# mc200 register map
Registers are 32-bit, access not given, no defined reset value unless marked. A register's access mark holds for its fields unless they carry their own. Addresses are absolute; registers are grouped by the start of their names; [hi:lo] are bit positions; {n}, {i} and the like mark numbered series.

## UART2
0x48020000 UART2_RBR_THR_DLL
  [7:0] RBR_THR_DLL
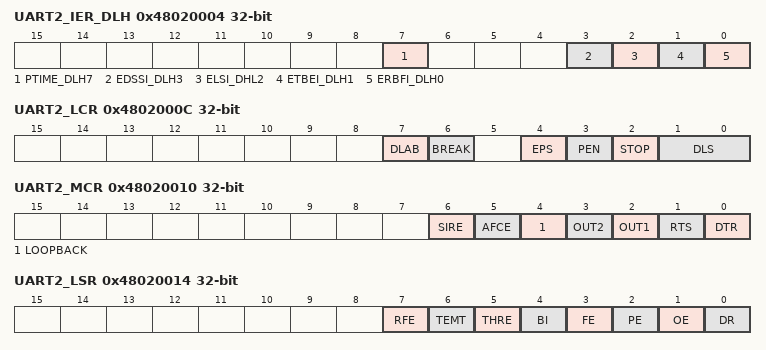
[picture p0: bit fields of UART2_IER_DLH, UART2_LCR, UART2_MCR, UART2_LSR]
0x48020004 UART2_IER_DLH
  [7] PTIME_DLH7, [3] EDSSI_DLH3, [2] ELSI_DHL2, [1] ETBEI_DLH1, [0] ERBFI_DLH0
0x48020008 UART2_IIR_FCR
  [31:0] DATA
0x4802000C UART2_LCR
  [7] DLAB, [6] BREAK, [4] EPS, [3] PEN, [2] STOP, [1:0] DLS
0x48020010 UART2_MCR
  [6] SIRE, [5] AFCE, [4] LOOPBACK, [3] OUT2, [2] OUT1, [1] RTS, [0] DTR
0x48020014 UART2_LSR
  [7] RFE, [6] TEMT, [5] THRE, [4] BI, [3] FE, [2] PE, [1] OE, [0] DR
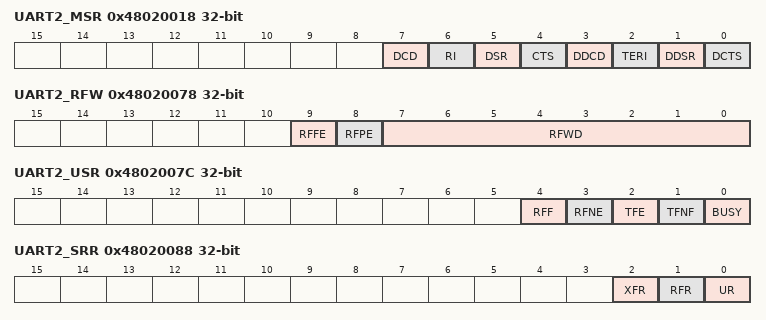
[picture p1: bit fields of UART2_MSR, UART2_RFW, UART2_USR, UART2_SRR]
0x48020018 UART2_MSR
  [7] DCD, [6] RI, [5] DSR, [4] CTS, [3] DDCD, [2] TERI, [1] DDSR, [0] DCTS
0x4802001C UART2_SCR
  [7:0] SCR
0x48020020 UART2_LPDLL
  [7:0] LPDLL
0x48020024 UART2_LPDLH
  [7:0] LPDLH
{0x48020030+4i} UART2_SRBR_STHR{i} (i=0..15)
  [7:0] SRBR_STHR{i}
0x48020070 UART2_FAR
  [0] SRBR_STHR
0x48020074 UART2_TFR
  [7:0] TFR
0x48020078 UART2_RFW
  [9] RFFE, [8] RFPE, [7:0] RFWD
0x4802007C UART2_USR
  [4] RFF, [3] RFNE, [2] TFE, [1] TFNF, [0] BUSY
0x48020080 UART2_TFL
  [4:0] TFL
0x48020084 UART2_RFL
  [4:0] RFL
0x48020088 UART2_SRR
  [2] XFR, [1] RFR, [0] UR
0x4802008C UART2_SRTS
  [0] SRTS
0x48020090 UART2_SBCR
  [0] SBCB
0x48020094 UART2_SDMAM
  [0] SDMAM
0x48020098 UART2_SFE
  [0] SFE
0x4802009C UART2_SRT
  [1:0] SRT
0x480200A0 UART2_STET
  [1:0] STET
0x480200A4 UART2_HTX
  [0] HTX
0x480200A8 UART2_DMASA
  [0] DMASA
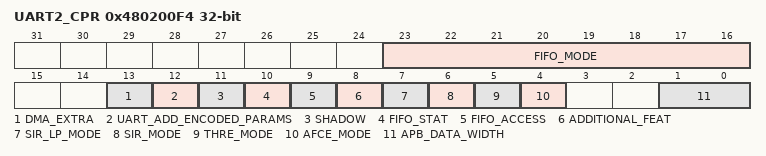
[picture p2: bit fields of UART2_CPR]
0x480200F4 UART2_CPR
  [23:16] FIFO_MODE, [13] DMA_EXTRA, [12] UART_ADD_ENCODED_PARAMS, [11] SHADOW, [10] FIFO_STAT, [9] FIFO_ACCESS, [8] ADDITIONAL_FEAT, [7] SIR_LP_MODE, [6] SIR_MODE, [5] THRE_MODE, [4] AFCE_MODE, [1:0] APB_DATA_WIDTH
0x480200F8 UART2_UCV
  [31:0] UART_COMPONENT_VERSION
0x480200FC UART2_CTR
  [31:0] PERIPHERAL_ID

## UART3
0x48030000 UART3_RBR_THR_DLL
  [7:0] RBR_THR_DLL
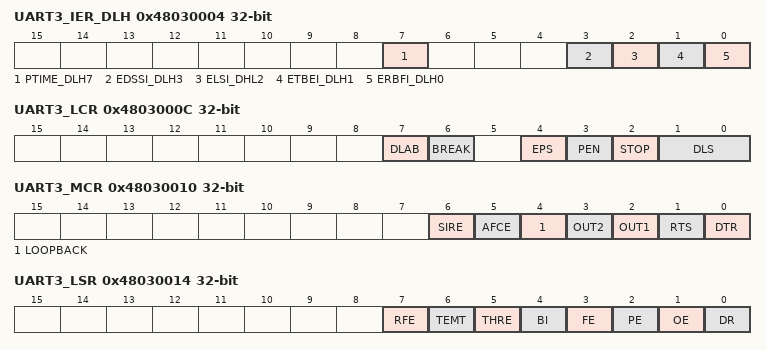
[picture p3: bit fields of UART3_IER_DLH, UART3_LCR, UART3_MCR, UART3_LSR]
0x48030004 UART3_IER_DLH
  [7] PTIME_DLH7, [3] EDSSI_DLH3, [2] ELSI_DHL2, [1] ETBEI_DLH1, [0] ERBFI_DLH0
0x48030008 UART3_IIR_FCR
  [31:0] DATA
0x4803000C UART3_LCR
  [7] DLAB, [6] BREAK, [4] EPS, [3] PEN, [2] STOP, [1:0] DLS
0x48030010 UART3_MCR
  [6] SIRE, [5] AFCE, [4] LOOPBACK, [3] OUT2, [2] OUT1, [1] RTS, [0] DTR
0x48030014 UART3_LSR
  [7] RFE, [6] TEMT, [5] THRE, [4] BI, [3] FE, [2] PE, [1] OE, [0] DR
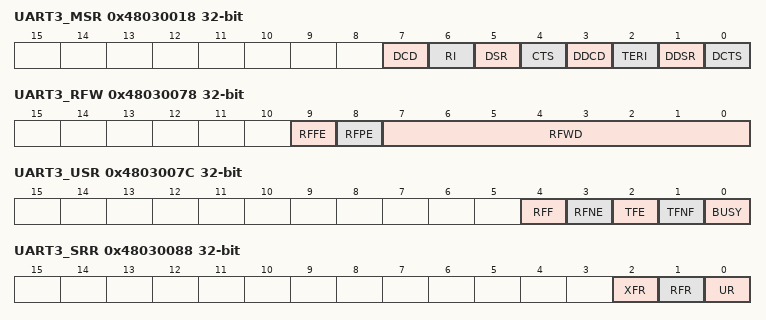
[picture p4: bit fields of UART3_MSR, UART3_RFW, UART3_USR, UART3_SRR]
0x48030018 UART3_MSR
  [7] DCD, [6] RI, [5] DSR, [4] CTS, [3] DDCD, [2] TERI, [1] DDSR, [0] DCTS
0x4803001C UART3_SCR
  [7:0] SCR
0x48030020 UART3_LPDLL
  [7:0] LPDLL
0x48030024 UART3_LPDLH
  [7:0] LPDLH
{0x48030030+4i} UART3_SRBR_STHR{i} (i=0..15)
  [7:0] SRBR_STHR{i}
0x48030070 UART3_FAR
  [0] SRBR_STHR
0x48030074 UART3_TFR
  [7:0] TFR
0x48030078 UART3_RFW
  [9] RFFE, [8] RFPE, [7:0] RFWD
0x4803007C UART3_USR
  [4] RFF, [3] RFNE, [2] TFE, [1] TFNF, [0] BUSY
0x48030080 UART3_TFL
  [4:0] TFL
0x48030084 UART3_RFL
  [4:0] RFL
0x48030088 UART3_SRR
  [2] XFR, [1] RFR, [0] UR
0x4803008C UART3_SRTS
  [0] SRTS
0x48030090 UART3_SBCR
  [0] SBCB
0x48030094 UART3_SDMAM
  [0] SDMAM
0x48030098 UART3_SFE
  [0] SFE
0x4803009C UART3_SRT
  [1:0] SRT
0x480300A0 UART3_STET
  [1:0] STET
0x480300A4 UART3_HTX
  [0] HTX
0x480300A8 UART3_DMASA
  [0] DMASA
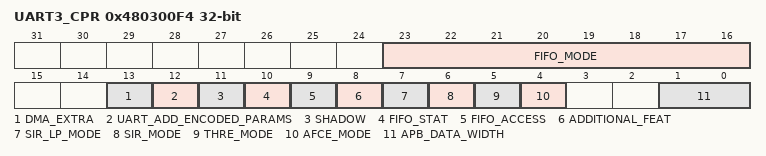
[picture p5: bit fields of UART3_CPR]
0x480300F4 UART3_CPR
  [23:16] FIFO_MODE, [13] DMA_EXTRA, [12] UART_ADD_ENCODED_PARAMS, [11] SHADOW, [10] FIFO_STAT, [9] FIFO_ACCESS, [8] ADDITIONAL_FEAT, [7] SIR_LP_MODE, [6] SIR_MODE, [5] THRE_MODE, [4] AFCE_MODE, [1:0] APB_DATA_WIDTH
0x480300F8 UART3_UCV
  [31:0] UART_COMPONENT_VERSION
0x480300FC UART3_CTR
  [31:0] PERIPHERAL_ID

## WDT
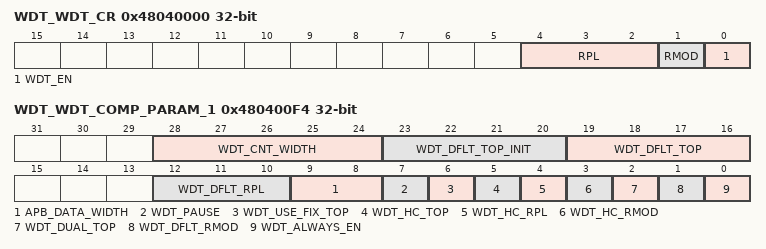
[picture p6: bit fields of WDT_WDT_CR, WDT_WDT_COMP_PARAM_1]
0x48040000 WDT_WDT_CR
  [4:2] RPL, [1] RMOD, [0] WDT_EN
0x48040004 WDT_WDT_TORR
  [3:0] TOP
0x48040008 WDT_WDT_CCVR
  [31:0] WDT_CCVR
0x4804000C WDT_WDT_CRR
  [7:0] WDT_CRR
0x48040010 WDT_WDT_STAT
  [0] WDT_STAT
0x48040014 WDT_WDT_EOI
  [0] WDT_EOI
0x480400E4 WDT_WDT_COMP_PARAM_5
  [31:0] DATA
0x480400E8 WDT_WDT_COMP_PARAM_4
  [31:0] DATA
0x480400EC WDT_WDT_COMP_PARAM_3
  [31:0] DATA
0x480400F0 WDT_WDT_COMP_PARAM_2
  [31:0] DATA
0x480400F4 WDT_WDT_COMP_PARAM_1
  [28:24] WDT_CNT_WIDTH, [23:20] WDT_DFLT_TOP_INIT, [19:16] WDT_DFLT_TOP, [12:10] WDT_DFLT_RPL, [9:8] APB_DATA_WIDTH, [7] WDT_PAUSE, [6] WDT_USE_FIX_TOP, [5] WDT_HC_TOP, [4] WDT_HC_RPL, [3] WDT_HC_RMOD, [2] WDT_DUAL_TOP, [1] WDT_DFLT_RMOD, [0] WDT_ALWAYS_EN
0x480400F8 WDT_WDT_COMP_VERSION
  [31:0] WDT_COMP_VERSION
0x480400FC WDT_WDT_COMP_TYPE
  [31:0] WDT_COMP_TYPE
